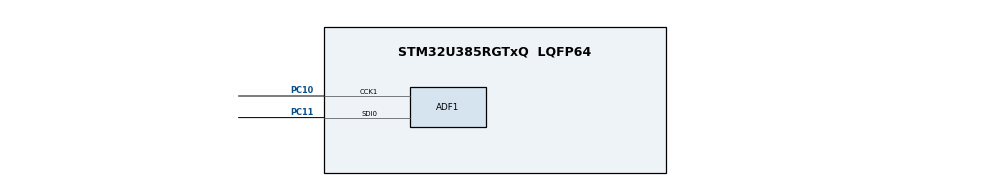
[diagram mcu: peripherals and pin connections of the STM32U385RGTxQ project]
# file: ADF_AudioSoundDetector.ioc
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ADF1.MDF_COMPARAM_ActivationOutputClock=ENABLE
ADF1.MDF_COMPARAM_Divider=12
ADF1.MDF_COMPARAM_ProcClockDivider=2
ADF1.MDF_DFLT0_CIC_Mode=MDF_ONE_FILTER_SINC5
ADF1.MDF_DFLT0_Decimation=32
ADF1.MDF_DFLT0_Gain=-10
ADF1.MDF_DFLT0_HighPassCutOffFrequency=MDF_HPF_CUTOFF_0_0025FPCM
ADF1.MDF_DFLT0_HighPassFilterActivation=ENABLE
ADF1.MDF_DFLT0_ReshapeFilterActivation=ENABLE
ADF1.MDF_DFLT0_SADActivation=ENABLE
ADF1.MDF_DFLT0_SADDataMemoryTransfer=MDF_SAD_MEMORY_TRANSFER_IN_DETECT
ADF1.MDF_DFLT0_SADHangoverWindow=MDF_SAD_HANGOVER_512_FRAMES
ADF1.MDF_DFLT0_SADHysteresis=ENABLE
ADF1.MDF_DFLT0_SADMinNoiseLevel=200
ADF1.MDF_DFLT0_SADSignalNoiseThreshold=MDF_SAD_SIGNAL_NOISE_6DB
ADF1.MDF_DFLT0_SADTriggerEvent=MDF_SAD_ENTER_EXIT_DETECT
ADF1.MDF_SITF0_Mode_Display=MDF_SITF_NORMAL_SPI_MODE
ADF1.MDF_SITF0_Threshold=31
CORTEX_M33_NS.userName=CORTEX_M33
GPDMA1.CIRCULARMODE_GPDMACH0=ENABLE
GPDMA1.DESTDATAWIDTH_GPDMACH0=DMA_DEST_DATAWIDTH_HALFWORD
GPDMA1.DESTINC_GPDMACH0=DMA_DINC_INCREMENTED
GPDMA1.IPHANDLE_GPDMACH0-SIMPLEREQUEST_GPDMACH0=__NULL
GPDMA1.LINKALLOCATEDPORT_CIRCULAR_GPDMACH0=DMA_LINK_ALLOCATED_PORT1
GPDMA1.PRIORITY_LL_CIRCULAR_GPDMACH0=DMA_LOW_PRIORITY_HIGH_WEIGHT
GPDMA1.REQUEST_GPDMACH0=GPDMA1_REQUEST_ADF1_FLT0
GPDMA1.SRCDATAWIDTH_GPDMACH0=DMA_SRC_DATAWIDTH_HALFWORD
GPDMA1.TRANSFERALLOCATEDPORTDEST_GPDMACH0=DMA_DEST_ALLOCATED_PORT1
Mcu.Family=STM32U3
Mcu.Name=STM32U385RGTxQ
Mcu.Package=LQFP64
NVIC.ADF1_IRQn=true\:0\:0\:false\:false\:true\:true\:true\:true
NVIC.GPDMA1_Channel0_IRQn=true\:0\:0\:false\:false\:true\:false\:true\:true
NVIC.PriorityGroup=NVIC_PRIORITYGROUP_4
PC10.GPIO_Speed=GPIO_SPEED_FREQ_VERY_HIGH
PC10.Mode=MOD_MDF_CCK1
PC10.Signal=ADF1_CCK1
PC11.GPIO_Speed=GPIO_SPEED_FREQ_VERY_HIGH
PC11.Mode=MOD_ADF_CCK
PC11.Signal=ADF1_SDI0
ProjectManager.HeapSize=0x200
ProjectManager.StackSize=0x400
ProjectManager.TargetToolchain=EWARM V9.20
RCC.ADCFreq_Value=96000000
RCC.AHBFreq_Value=96000000
RCC.APB1Freq_Value=96000000
RCC.APB1TimFreq_Value=96000000
RCC.APB2Freq_Value=96000000
RCC.APB2TimFreq_Value=96000000
RCC.APB3Freq_Value=96000000
RCC.AdfClockSelection=RCC_ADF1CLKSOURCE_MSIK
RCC.CortexFreq_Value=12000000
RCC.HCLKFreq_Value=96000000
RCC.HSE_VALUE=16000000
RCC.HSI48_VALUE=48000000
RCC.HSI_VALUE=16000000
RCC.LSE_VALUE=32768
RCC.LSIDIV_VALUE=32000
RCC.MSIKDIV=RCC_MSI_DIV2
RCC.MSISDIV=RCC_MSI_DIV1
RCC.SYSCLKFreq_VALUE=96000000
RCC.USBFreq_Value=96000000
VP_GPDMA1_VS_GPDMACH0.Mode=SIMPLEREQUEST_GPDMACH0
VP_ICACHE_VS_ICACHE.Mode=DirectMappedCache
VP_PWR_VS_DBSignals.Mode=DisableDeadBatterySignals
VP_PWR_VS_LPOM.Mode=PowerOptimisation
VP_PWR_VS_SECSignals.Mode=Security/Privilege
board=custom

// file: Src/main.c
/* USER CODE BEGIN Header */
/**
  ******************************************************************************
  * @file           : main.c
  * @brief          : Main program body
  ******************************************************************************
  * @attention
  *
  * Copyright (c) 2024 STMicroelectronics.
  * All rights reserved.
  *
  * This software is licensed under terms that can be found in the LICENSE file
  * in the root directory of this software component.
  * If no LICENSE file comes with this software, it is provided AS-IS.
  *
  ******************************************************************************
  */
/* USER CODE END Header */
#include "main.h"

/* USER CODE BEGIN Includes */
#include "stm32u3xx_nucleo.h"
/* USER CODE END Includes */

MDF_HandleTypeDef AdfHandle0;
MDF_FilterConfigTypeDef AdfFilterConfig0;
DMA_NodeTypeDef Node_GPDMA1_Channel0;
DMA_QListTypeDef List_GPDMA1_Channel0;
DMA_HandleTypeDef handle_GPDMA1_Channel0;

/* USER CODE BEGIN PV */
static int16_t PcmBuffer[2048U];
/* USER CODE END PV */

void SystemClock_Config(void);
static void MX_GPIO_Init(void);
static void MX_GPDMA1_Init(void);
static void MX_ADF1_Init(void);
static void MX_ICACHE_Init(void);

int main(void)
{

  /* USER CODE BEGIN 1 */
  MDF_DmaConfigTypeDef dma_config;
  /* USER CODE END 1 */

  /* MCU Configuration--------------------------------------------------------*/

  /* Reset of all peripherals, Initializes the Flash interface and the Systick. */
  HAL_Init();

  /* Configure the system clock */
  SystemClock_Config();

  /* USER CODE BEGIN SysInit */
  if (BSP_ERROR_NONE != BSP_LED_Init(LED_GREEN))
  {
    Error_Handler();
  }
  /* USER CODE END SysInit */

  /* Initialize all configured peripherals */
  MX_GPIO_Init();
  MX_GPDMA1_Init();
  MX_ADF1_Init();
  MX_ICACHE_Init();
  /* USER CODE BEGIN 2 */
  /* Start ADF Acquisition */
  dma_config.Address    = (uint32_t)&PcmBuffer[0];
  dma_config.DataLength = 4096U;
  dma_config.MsbOnly    = ENABLE;
  if (HAL_MDF_AcqStart_DMA(&AdfHandle0, &AdfFilterConfig0, &dma_config) != HAL_OK)
  {
    Error_Handler();
  }
  /* USER CODE END 2 */

  /* Infinite loop */
  while (1)
  {

  }
}

void SystemClock_Config(void)
{
  RCC_OscInitTypeDef RCC_OscInitStruct = {0};
  RCC_ClkInitTypeDef RCC_ClkInitStruct = {0};

  /** Enable Epod Booster
  */
  if (HAL_RCCEx_EpodBoosterClkConfig(RCC_EPODBOOSTER_SOURCE_MSIS, RCC_EPODBOOSTER_DIV1) != HAL_OK)
  {
    Error_Handler();
  }

  if (HAL_PWREx_EnableEpodBooster() != HAL_OK)
  {
    Error_Handler();
  }

  /** Configure the main internal regulator output voltage
  */
  if (HAL_PWREx_ControlVoltageScaling(PWR_REGULATOR_VOLTAGE_SCALE1) != HAL_OK)
  {
    Error_Handler();
  }

  /** Set Flash latency before increasing MSIS
  */
  __HAL_FLASH_SET_LATENCY(FLASH_LATENCY_2);

  /** Initializes the CPU, AHB and APB buses clocks
  */
  RCC_OscInitStruct.OscillatorType = RCC_OSCILLATORTYPE_MSIS|RCC_OSCILLATORTYPE_MSIK;
  RCC_OscInitStruct.MSISState = RCC_MSI_ON;
  RCC_OscInitStruct.MSISSource = RCC_MSI_RC0;
  RCC_OscInitStruct.MSISDiv = RCC_MSI_DIV1;
  RCC_OscInitStruct.MSIKState = RCC_MSI_ON;
  RCC_OscInitStruct.MSIKSource = RCC_MSI_RC0;
  RCC_OscInitStruct.MSIKDiv = RCC_MSI_DIV2;

  if (HAL_RCC_OscConfig(&RCC_OscInitStruct) != HAL_OK)
  {
    Error_Handler();
  }

  /** Initializes the CPU, AHB and APB buses clocks
  */
  RCC_ClkInitStruct.ClockType = RCC_CLOCKTYPE_HCLK|RCC_CLOCKTYPE_SYSCLK
                              |RCC_CLOCKTYPE_PCLK1|RCC_CLOCKTYPE_PCLK2
                              |RCC_CLOCKTYPE_PCLK3;
  RCC_ClkInitStruct.SYSCLKSource = RCC_SYSCLKSOURCE_MSIS;
  RCC_ClkInitStruct.AHBCLKDivider = RCC_SYSCLK_DIV1;
  RCC_ClkInitStruct.APB1CLKDivider = RCC_HCLK_DIV1;
  RCC_ClkInitStruct.APB2CLKDivider = RCC_HCLK_DIV1;
  RCC_ClkInitStruct.APB3CLKDivider = RCC_HCLK_DIV1;

  if (HAL_RCC_ClockConfig(&RCC_ClkInitStruct, FLASH_LATENCY_2) != HAL_OK)
  {
    Error_Handler();
  }
}

static void MX_ADF1_Init(void)
{

  /**
    AdfHandle0 structure initialization and HAL_MDF_Init function call
  */
  AdfHandle0.Instance = ADF1_Filter0;
  AdfHandle0.Init.CommonParam.ProcClockDivider = 2;
  AdfHandle0.Init.CommonParam.OutputClock.Activation = ENABLE;
  AdfHandle0.Init.CommonParam.OutputClock.Pins = MDF_OUTPUT_CLOCK_1;
  AdfHandle0.Init.CommonParam.OutputClock.Divider = 12;
  AdfHandle0.Init.CommonParam.OutputClock.Trigger.Activation = DISABLE;
  AdfHandle0.Init.SerialInterface.Activation = ENABLE;
  AdfHandle0.Init.SerialInterface.Mode = MDF_SITF_NORMAL_SPI_MODE;
  AdfHandle0.Init.SerialInterface.ClockSource = MDF_SITF_CCK1_SOURCE;
  AdfHandle0.Init.SerialInterface.Threshold = 31;
  AdfHandle0.Init.FilterBistream = MDF_BITSTREAM0_FALLING;
  if (HAL_MDF_Init(&AdfHandle0) != HAL_OK)
  {
    Error_Handler();
  }

  /**
    AdfFilterConfig0 structure initialization

    WARNING : only structure is filled, no specific init function call for filter
  */
  AdfFilterConfig0.DataSource = MDF_DATA_SOURCE_BSMX;
  AdfFilterConfig0.Delay = 0;
  AdfFilterConfig0.CicMode = MDF_ONE_FILTER_SINC5;
  AdfFilterConfig0.DecimationRatio = 32;
  AdfFilterConfig0.Gain = -10;
  AdfFilterConfig0.ReshapeFilter.Activation = ENABLE;
  AdfFilterConfig0.ReshapeFilter.DecimationRatio = MDF_RSF_DECIMATION_RATIO_4;
  AdfFilterConfig0.HighPassFilter.Activation = ENABLE;
  AdfFilterConfig0.HighPassFilter.CutOffFrequency = MDF_HPF_CUTOFF_0_0025FPCM;
  AdfFilterConfig0.SoundActivity.Activation = ENABLE;
  AdfFilterConfig0.SoundActivity.Mode = MDF_SAD_VOICE_ACTIVITY_DETECTOR;
  AdfFilterConfig0.SoundActivity.FrameSize = MDF_SAD_8_PCM_SAMPLES;
  AdfFilterConfig0.SoundActivity.Hysteresis = ENABLE;
  AdfFilterConfig0.SoundActivity.SoundTriggerEvent = MDF_SAD_ENTER_EXIT_DETECT;
  AdfFilterConfig0.SoundActivity.DataMemoryTransfer = MDF_SAD_MEMORY_TRANSFER_IN_DETECT;
  AdfFilterConfig0.SoundActivity.MinNoiseLevel = 200;
  AdfFilterConfig0.SoundActivity.HangoverWindow = MDF_SAD_HANGOVER_512_FRAMES;
  AdfFilterConfig0.SoundActivity.LearningFrames = MDF_SAD_LEARNING_2_FRAMES;
  AdfFilterConfig0.SoundActivity.AmbientNoiseSlope = 0;
  AdfFilterConfig0.SoundActivity.SignalNoiseThreshold = MDF_SAD_SIGNAL_NOISE_6DB;
  AdfFilterConfig0.SoundActivity.SoundLevelInterrupt = DISABLE;
  AdfFilterConfig0.AcquisitionMode = MDF_MODE_ASYNC_CONT;
  AdfFilterConfig0.FifoThreshold = MDF_FIFO_THRESHOLD_NOT_EMPTY;
  AdfFilterConfig0.DiscardSamples = 0;

}

static void MX_GPDMA1_Init(void)
{

  /* Peripheral clock enable */
  __HAL_RCC_GPDMA1_CLK_ENABLE();

  /* GPDMA1 interrupt Init */
    HAL_NVIC_SetPriority(GPDMA1_Channel0_IRQn, 0, 0);
    HAL_NVIC_EnableIRQ(GPDMA1_Channel0_IRQn);

}

static void MX_ICACHE_Init(void)
{

  /** Enable instruction cache in 1-way (direct mapped cache)
  */
  if (HAL_ICACHE_ConfigAssociativityMode(ICACHE_1WAY) != HAL_OK)
  {
    Error_Handler();
  }
  if (HAL_ICACHE_Enable() != HAL_OK)
  {
    Error_Handler();
  }

}

static void MX_GPIO_Init(void)
{

  /* GPIO Ports Clock Enable */
  __HAL_RCC_GPIOC_CLK_ENABLE();

}

/* USER CODE BEGIN 4 */
/**
  * @brief  MDF sound activity detector callback.
  * @param  hmdf MDF handle.
  * @retval None.
  */
void HAL_MDF_SadCallback(MDF_HandleTypeDef *hmdf)
{
  UNUSED(hmdf);

  BSP_LED_Toggle(LED_GREEN);
}

/**
  * @brief  MDF acquisition half complete callback.
  * @param  hmdf MDF handle.
  * @retval None.
  */
void HAL_MDF_AcqHalfCpltCallback(MDF_HandleTypeDef *hmdf)
{
  UNUSED(hmdf);

  BSP_LED_Toggle(LED_GREEN);
}

/**
  * @brief  MDF acquisition complete callback.
  * @param  hmdf MDF handle.
  * @retval None.
  */
void HAL_MDF_AcqCpltCallback(MDF_HandleTypeDef *hmdf)
{
  UNUSED(hmdf);

  BSP_LED_Toggle(LED_GREEN);
}
/* USER CODE END 4 */

void Error_Handler(void)
{
  /* USER CODE BEGIN Error_Handler_Debug */
  /* User can add his own implementation to report the HAL error return state */
  while (1)
  {
    /* Toggle green led for error */
    (void) BSP_LED_Toggle(LED_GREEN);
    HAL_Delay(500);
  }
  /* USER CODE END Error_Handler_Debug */
}
